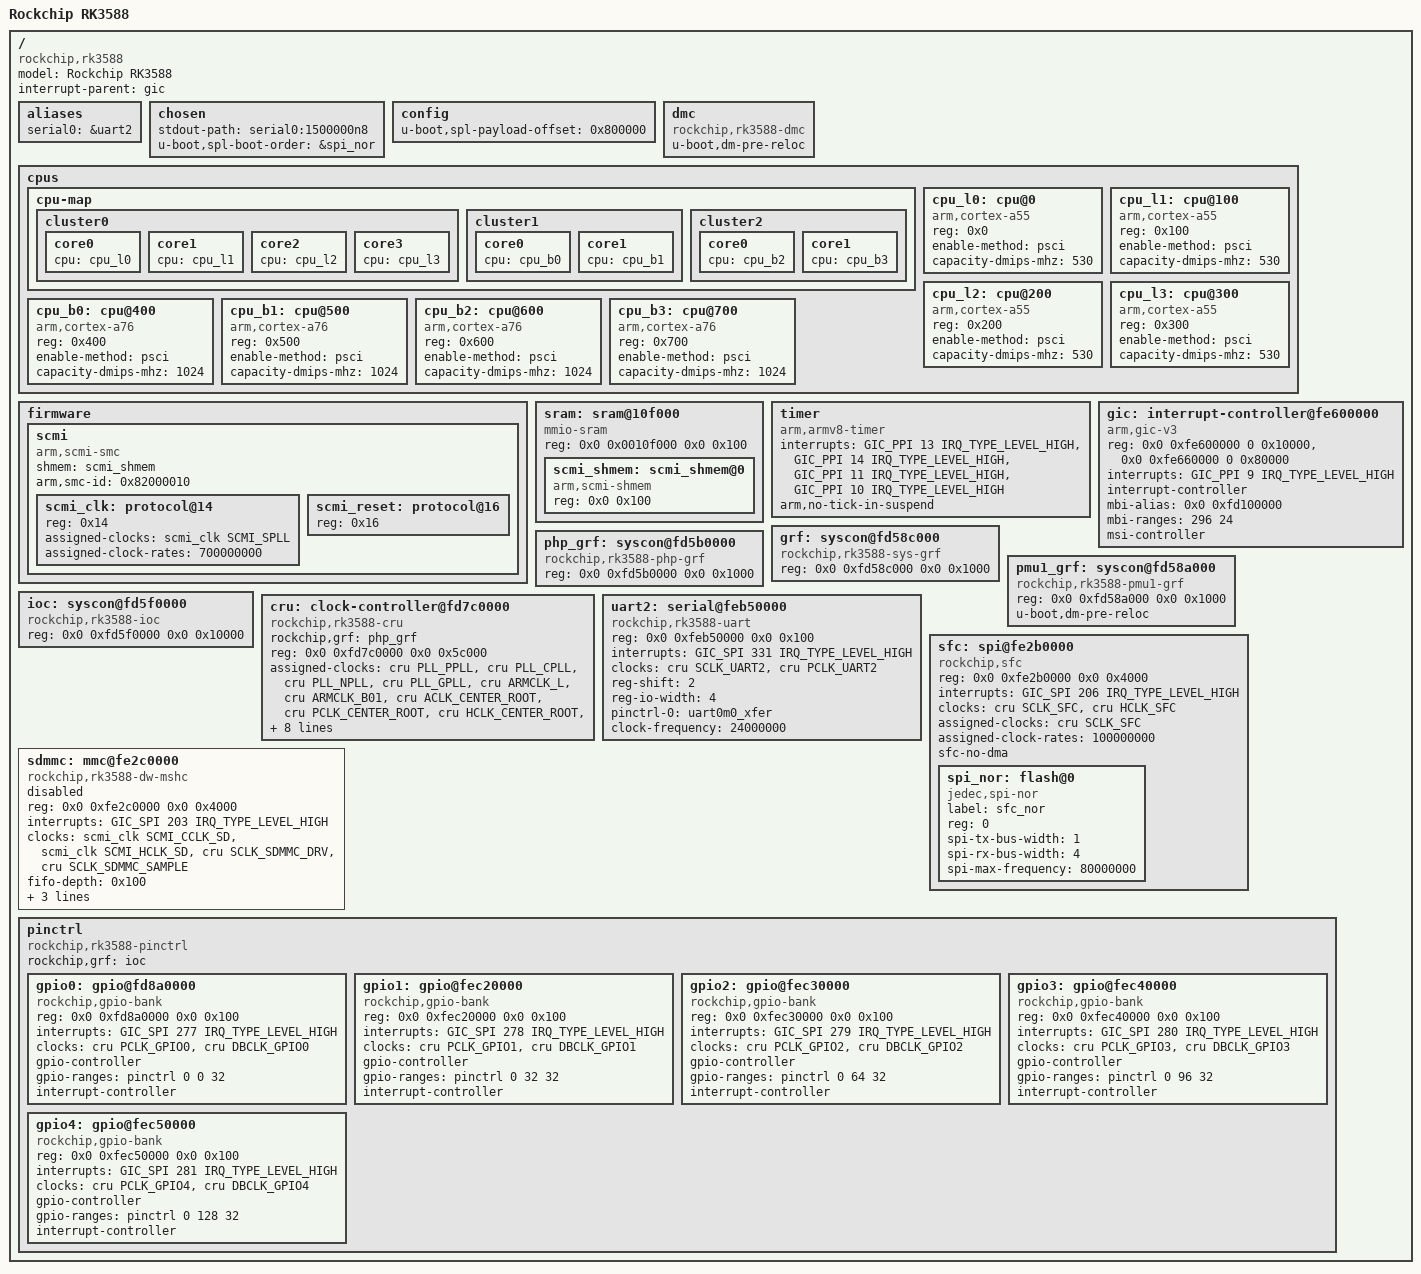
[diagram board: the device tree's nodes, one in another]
// SPDX-License-Identifier: (GPL-2.0+ OR MIT)
/*
 * Copyright (c) 2021 Rockchip Electronics Co., Ltd.
 */

/dts-v1/;
#include <dt-bindings/clock/rk3588-cru.h>
#include <dt-bindings/interrupt-controller/arm-gic.h>
#include <dt-bindings/interrupt-controller/irq.h>
#include <dt-bindings/phy/phy.h>
#include <dt-bindings/pinctrl/rockchip.h>
#include <dt-bindings/soc/rockchip,boot-mode.h>
#include <dt-bindings/thermal/thermal.h>

/ {
    model = "Rockchip RK3588";
    compatible = "rockchip,rk3588";

    interrupt-parent = <&gic>;
    #address-cells = <2>;
    #size-cells = <2>;

    aliases {
        serial0 = &uart2;
    };

    chosen {
        stdout-path = "serial0:1500000n8";
        u-boot,spl-boot-order = &spi_nor;
    };

    config {
        u-boot,spl-payload-offset = <0x800000>;
    };

    dmc: dmc {
		compatible = "rockchip,rk3588-dmc";
		u-boot,dm-pre-reloc;
		status = "okay";
	};

    cpus {
        #address-cells = <1>;
        #size-cells = <0>;

        cpu-map {
            cluster0 {
                core0 {
                    cpu = <&cpu_l0>;
                };
                core1 {
                    cpu = <&cpu_l1>;
                };
                core2 {
                    cpu = <&cpu_l2>;
                };
                core3 {
                    cpu = <&cpu_l3>;
                };
            };
            cluster1 {
                core0 {
                    cpu = <&cpu_b0>;
                };
                core1 {
                    cpu = <&cpu_b1>;
                };
            };
            cluster2 {
                core0 {
                    cpu = <&cpu_b2>;
                };
                core1 {
                    cpu = <&cpu_b3>;
                };
            };
        };

        cpu_l0: cpu@0 {
            device_type = "cpu";
            compatible = "arm,cortex-a55";
            reg = <0x0>;
            enable-method = "psci";
            capacity-dmips-mhz = <530>;
        };

        cpu_l1: cpu@100 {
            device_type = "cpu";
            compatible = "arm,cortex-a55";
            reg = <0x100>;
            enable-method = "psci";
            capacity-dmips-mhz = <530>;
        };

        cpu_l2: cpu@200 {
            device_type = "cpu";
            compatible = "arm,cortex-a55";
            reg = <0x200>;
            enable-method = "psci";
            capacity-dmips-mhz = <530>;
        };

        cpu_l3: cpu@300 {
            device_type = "cpu";
            compatible = "arm,cortex-a55";
            reg = <0x300>;
            enable-method = "psci";
            capacity-dmips-mhz = <530>;
        };

        cpu_b0: cpu@400 {
            device_type = "cpu";
            compatible = "arm,cortex-a76";
            reg = <0x400>;
            enable-method = "psci";
            capacity-dmips-mhz = <1024>;
        };

        cpu_b1: cpu@500 {
            device_type = "cpu";
            compatible = "arm,cortex-a76";
            reg = <0x500>;
            enable-method = "psci";
            capacity-dmips-mhz = <1024>;
        };

        cpu_b2: cpu@600 {
            device_type = "cpu";
            compatible = "arm,cortex-a76";
            reg = <0x600>;
            enable-method = "psci";
            capacity-dmips-mhz = <1024>;
        };

        cpu_b3: cpu@700 {
            device_type = "cpu";
            compatible = "arm,cortex-a76";
            reg = <0x700>;
            enable-method = "psci";
            capacity-dmips-mhz = <1024>;
        };
    };


    firmware: firmware {
        scmi: scmi {
            compatible = "arm,scmi-smc";
            shmem = <&scmi_shmem>;
            arm,smc-id = <0x82000010>;
            #address-cells = <1>;
            #size-cells = <0>;

            scmi_clk: protocol@14 {
                reg = <0x14>;
                #clock-cells = <1>;

                assigned-clocks = <&scmi_clk SCMI_SPLL>;
                assigned-clock-rates = <700000000>;
            };

            scmi_reset: protocol@16 {
                reg = <0x16>;
                #reset-cells = <1>;
            };
        };
    };

    sram: sram@10f000 {
        compatible = "mmio-sram";
        reg = <0x0 0x0010f000 0x0 0x100>;
        #address-cells = <1>;
        #size-cells = <1>;
        ranges = <0 0x0 0x0010f000 0x100>;

        scmi_shmem: scmi_shmem@0 {
            compatible = "arm,scmi-shmem";
            reg = <0x0 0x100>;
        };
    };

    timer {
        compatible = "arm,armv8-timer";
        interrupts = <GIC_PPI 13 IRQ_TYPE_LEVEL_HIGH>,
                 <GIC_PPI 14 IRQ_TYPE_LEVEL_HIGH>,
                 <GIC_PPI 11 IRQ_TYPE_LEVEL_HIGH>,
                 <GIC_PPI 10 IRQ_TYPE_LEVEL_HIGH>;
        arm,no-tick-in-suspend;
        status = "okay";
        u-boot,dm-spl;
    };

    gic: interrupt-controller@fe600000 {
        compatible = "arm,gic-v3";
        reg = <0x0 0xfe600000 0 0x10000>, /* GICD */
              <0x0 0xfe660000 0 0x80000>; /* GICR */
        interrupts = <GIC_PPI 9 IRQ_TYPE_LEVEL_HIGH>;
        interrupt-controller;
        #interrupt-cells = <3>;
        mbi-alias = <0x0 0xfd100000>;
        mbi-ranges = <296 24>;
        msi-controller;
        status = "okay";
        u-boot,dm-spl;
    };

    grf: syscon@fd58c000 {
        compatible = "rockchip,rk3588-sys-grf", "syscon", "simple-mfd";
        reg = <0x0 0xfd58c000 0x0 0x1000>;
        status = "okay";
        u-boot,dm-spl;
    };

    php_grf: syscon@fd5b0000 {
		compatible = "rockchip,rk3588-php-grf", "syscon", "simple-mfd";
		reg = <0x0 0xfd5b0000 0x0 0x1000>;
        status = "okay";
        u-boot,dm-spl;
	};

    pmu1_grf: syscon@fd58a000 {
		compatible = "rockchip,rk3588-pmu1-grf", "syscon", "simple-mfd";
		reg = <0x0 0xfd58a000 0x0 0x1000>;
        status = "okay";
        u-boot,dm-pre-reloc;
	};

    ioc: syscon@fd5f0000 {
        compatible = "rockchip,rk3588-ioc", "syscon";
        reg = <0x0 0xfd5f0000 0x0 0x10000>;
        u-boot,dm-spl;
    };

    cru: clock-controller@fd7c0000 {
		compatible = "rockchip,rk3588-cru";
		rockchip,grf = <&php_grf>;
		reg = <0x0 0xfd7c0000 0x0 0x5c000>;
		#clock-cells = <1>;
		#reset-cells = <1>;
        status = "okay";
        u-boot,dm-spl;

        assigned-clocks =
			<&cru PLL_PPLL>, <&cru PLL_CPLL>,
			<&cru PLL_NPLL>, <&cru PLL_GPLL>,
			<&cru ARMCLK_L>, <&cru ARMCLK_B01>,
			<&cru ACLK_CENTER_ROOT>, <&cru PCLK_CENTER_ROOT>,
			<&cru HCLK_CENTER_ROOT>, <&cru ACLK_CENTER_LOW_ROOT>,
			<&cru ACLK_TOP_ROOT>, <&cru PCLK_TOP_ROOT>,
			<&cru ACLK_LOW_TOP_ROOT>, <&cru PCLK_PMU0_ROOT>,
			<&cru HCLK_PMU_CM0_ROOT>;
		assigned-clock-rates =
			<100000000>, <1500000000>,
			<850000000>, <1188000000>,
			<816000000>, <1008000000>,
			<600000000>, <200000000>,
			<400000000>, <500000000>,
			<800000000>, <100000000>,
			<400000000>, <100000000>,
			<200000000>;
	};

    uart2: serial@feb50000 {
        compatible = "rockchip,rk3588-uart", "snps,dw-apb-uart";
        reg = <0x0 0xfeb50000 0x0 0x100>;
        interrupts = <GIC_SPI 331 IRQ_TYPE_LEVEL_HIGH>;
        clocks = <&cru SCLK_UART2>, <&cru PCLK_UART2>;
        clock-names = "baudclk", "apb_pclk";
        reg-shift = <2>;
        reg-io-width = <4>;
        pinctrl-names = "default";
        pinctrl-0 = <&uart0m0_xfer>;
        clock-frequency = <24000000>;
        u-boot,dm-spl;
        status = "okay";
    };

    sfc: spi@fe2b0000 {
		compatible = "rockchip,sfc";
		reg = <0x0 0xfe2b0000 0x0 0x4000>;
		interrupts = <GIC_SPI 206 IRQ_TYPE_LEVEL_HIGH>;
		clocks = <&cru SCLK_SFC>, <&cru HCLK_SFC>;
		clock-names = "clk_sfc", "hclk_sfc";
		assigned-clocks = <&cru SCLK_SFC>;
		assigned-clock-rates = <100000000>;
		#address-cells = <1>;
		#size-cells = <0>;
        u-boot,dm-spl;
        sfc-no-dma;
        status = "okay";

        spi_nor: flash@0 {
            status = "okay";
            u-boot,dm-spl;
            compatible = "jedec,spi-nor";
            label = "sfc_nor";
            reg = <0>;
            spi-tx-bus-width = <1>;
            spi-rx-bus-width = <4>;
            spi-max-frequency = <80000000>;
        };
    };

    sdmmc: mmc@fe2c0000 {
        compatible = "rockchip,rk3588-dw-mshc", "rockchip,rk3288-dw-mshc";
        reg = <0x0 0xfe2c0000 0x0 0x4000>;
        interrupts = <GIC_SPI 203 IRQ_TYPE_LEVEL_HIGH>;
        clocks = <&scmi_clk SCMI_CCLK_SD>, <&scmi_clk SCMI_HCLK_SD>,
             <&cru SCLK_SDMMC_DRV>, <&cru SCLK_SDMMC_SAMPLE>;
        clock-names = "ciu", "biu", "ciu-drive", "ciu-sample";
        fifo-depth = <0x100>;
        max-frequency = <200000000>;
        pinctrl-names = "default";
        pinctrl-0 = <&sdmmc_clk &sdmmc_cmd &sdmmc_det &sdmmc_bus4>;
        u-boot,dm-spl;
        status = "disabled";
    };

    pinctrl: pinctrl {
        compatible = "rockchip,rk3588-pinctrl";
        rockchip,grf = <&ioc>;
        #address-cells = <2>;
        #size-cells = <2>;
        ranges;
        u-boot,dm-spl;

        gpio0: gpio@fd8a0000 {
            compatible = "rockchip,gpio-bank";
            reg = <0x0 0xfd8a0000 0x0 0x100>;
            interrupts = <GIC_SPI 277 IRQ_TYPE_LEVEL_HIGH>;
            clocks = <&cru PCLK_GPIO0>, <&cru DBCLK_GPIO0>;

            gpio-controller;
            #gpio-cells = <2>;
            gpio-ranges = <&pinctrl 0 0 32>;
            interrupt-controller;
            #interrupt-cells = <2>;
            u-boot,dm-spl;
        };

        gpio1: gpio@fec20000 {
            compatible = "rockchip,gpio-bank";
            reg = <0x0 0xfec20000 0x0 0x100>;
            interrupts = <GIC_SPI 278 IRQ_TYPE_LEVEL_HIGH>;
            clocks = <&cru PCLK_GPIO1>, <&cru DBCLK_GPIO1>;

            gpio-controller;
            #gpio-cells = <2>;
            gpio-ranges = <&pinctrl 0 32 32>;
            interrupt-controller;
            #interrupt-cells = <2>;
            u-boot,dm-spl;
        };

        gpio2: gpio@fec30000 {
            compatible = "rockchip,gpio-bank";
            reg = <0x0 0xfec30000 0x0 0x100>;
            interrupts = <GIC_SPI 279 IRQ_TYPE_LEVEL_HIGH>;
            clocks = <&cru PCLK_GPIO2>, <&cru DBCLK_GPIO2>;

            gpio-controller;
            #gpio-cells = <2>;
            gpio-ranges = <&pinctrl 0 64 32>;
            interrupt-controller;
            #interrupt-cells = <2>;
            u-boot,dm-spl;
        };

        gpio3: gpio@fec40000 {
            compatible = "rockchip,gpio-bank";
            reg = <0x0 0xfec40000 0x0 0x100>;
            interrupts = <GIC_SPI 280 IRQ_TYPE_LEVEL_HIGH>;
            clocks = <&cru PCLK_GPIO3>, <&cru DBCLK_GPIO3>;

            gpio-controller;
            #gpio-cells = <2>;
            gpio-ranges = <&pinctrl 0 96 32>;
            interrupt-controller;
            #interrupt-cells = <2>;
            u-boot,dm-spl;
        };

        gpio4: gpio@fec50000 {
            compatible = "rockchip,gpio-bank";
            reg = <0x0 0xfec50000 0x0 0x100>;
            interrupts = <GIC_SPI 281 IRQ_TYPE_LEVEL_HIGH>;
            clocks = <&cru PCLK_GPIO4>, <&cru DBCLK_GPIO4>;

            gpio-controller;
            #gpio-cells = <2>;
            gpio-ranges = <&pinctrl 0 128 32>;
            interrupt-controller;
            #interrupt-cells = <2>;
            u-boot,dm-spl;
        };
    };
};

#include "rk3588-pinctrl.dtsi"
